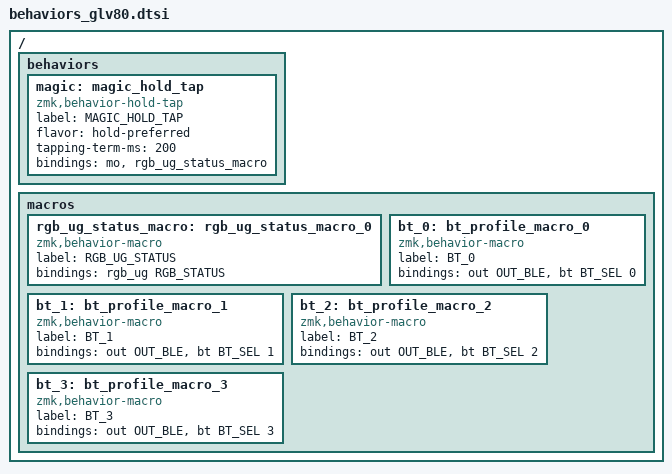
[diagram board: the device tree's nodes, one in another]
/ {
    behaviors {
        magic: magic_hold_tap {
            compatible = "zmk,behavior-hold-tap";
            label = "MAGIC_HOLD_TAP";
            #binding-cells = <2>;
            flavor = "hold-preferred";
            tapping-term-ms = <200>;
            bindings = <&mo>, <&rgb_ug_status_macro>;
        };
    };

    // these are from the glove80 default config:
    macros {
        rgb_ug_status_macro: rgb_ug_status_macro_0 {
            label = "RGB_UG_STATUS";
            compatible = "zmk,behavior-macro";
            #binding-cells = <0>;
            bindings
                = <&rgb_ug RGB_STATUS>;
        };

        bt_0: bt_profile_macro_0 {
            label = "BT_0";
            compatible = "zmk,behavior-macro";
            #binding-cells = <0>;
            bindings
                = <&out OUT_BLE>,
                  <&bt BT_SEL 0>;
        };

        bt_1: bt_profile_macro_1 {
            label = "BT_1";
            compatible = "zmk,behavior-macro";
            #binding-cells = <0>;
            bindings
                = <&out OUT_BLE>,
                  <&bt BT_SEL 1>;
        };

        bt_2: bt_profile_macro_2 {
            label = "BT_2";
            compatible = "zmk,behavior-macro";
            #binding-cells = <0>;
            bindings
                = <&out OUT_BLE>,
                  <&bt BT_SEL 2>;
        };

        bt_3: bt_profile_macro_3 {
            label = "BT_3";
            compatible = "zmk,behavior-macro";
            #binding-cells = <0>;
            bindings
                = <&out OUT_BLE>,
                  <&bt BT_SEL 3>;
        };
    };
};

